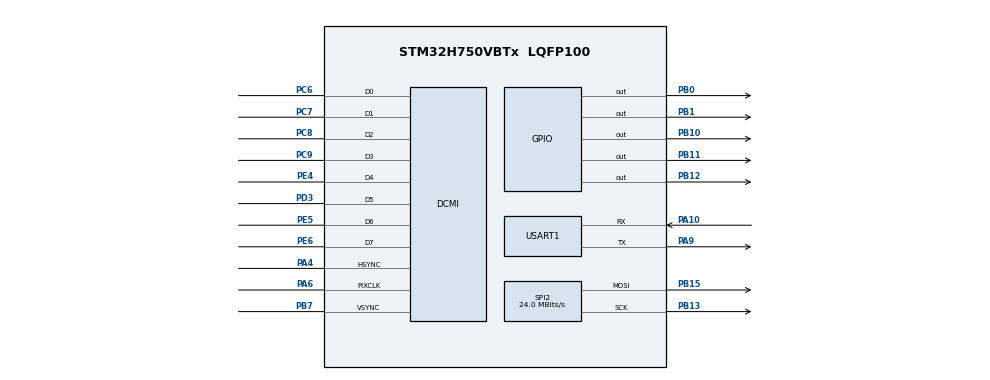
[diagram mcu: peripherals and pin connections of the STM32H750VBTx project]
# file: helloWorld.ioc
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DCMI.JPEGMode=DCMI_JPEG_ENABLE
Mcu.Family=STM32H7
Mcu.Name=STM32H750VBTx
Mcu.Package=LQFP100
NVIC.PriorityGroup=NVIC_PRIORITYGROUP_4
PA10.Mode=Asynchronous
PA10.Signal=USART1_RX
PA4.Mode=Slave_8_bits_External_Synchro
PA4.Signal=DCMI_HSYNC
PA6.Mode=Slave_8_bits_External_Synchro
PA6.Signal=DCMI_PIXCLK
PA9.Mode=Asynchronous
PA9.Signal=USART1_TX
PB0.Signal=GPIO_Output
PB1.Signal=GPIO_Output
PB10.Signal=GPIO_Output
PB11.Signal=GPIO_Output
PB12.Signal=GPIO_Output
PB13.Mode=TX_Only_Simplex_Unidirect_Master
PB13.Signal=SPI2_SCK
PB15.Mode=TX_Only_Simplex_Unidirect_Master
PB15.Signal=SPI2_MOSI
PB7.Mode=Slave_8_bits_External_Synchro
PB7.Signal=DCMI_VSYNC
PC6.Mode=Slave_8_bits_External_Synchro
PC6.Signal=DCMI_D0
PC7.Mode=Slave_8_bits_External_Synchro
PC7.Signal=DCMI_D1
PC8.Mode=Slave_8_bits_External_Synchro
PC8.Signal=DCMI_D2
PC9.Mode=Slave_8_bits_External_Synchro
PC9.Signal=DCMI_D3
PD3.Mode=Slave_8_bits_External_Synchro
PD3.Signal=DCMI_D5
PE4.Mode=Slave_8_bits_External_Synchro
PE4.Signal=DCMI_D4
PE5.Mode=Slave_8_bits_External_Synchro
PE5.Signal=DCMI_D6
PE6.Mode=Slave_8_bits_External_Synchro
PE6.Signal=DCMI_D7
ProjectManager.HeapSize=0x200
ProjectManager.StackSize=0x400
ProjectManager.TargetToolchain=MDK-ARM V5.32
RCC.ADCFreq_Value=129000000
RCC.APB1Freq_Value=120000000
RCC.APB2Freq_Value=120000000
RCC.APB3Freq_Value=120000000
RCC.APB4Freq_Value=120000000
RCC.CortexFreq_Value=480000000
RCC.D1PPRE=RCC_APB3_DIV2
RCC.D2PPRE1=RCC_APB1_DIV2
RCC.D2PPRE2=RCC_APB2_DIV2
RCC.D3PPRE=RCC_APB4_DIV2
RCC.DIVM1=4
RCC.DIVN1=60
RCC.DIVQ1=5
RCC.HCLKFreq_Value=240000000
RCC.HPRE=RCC_HCLK_DIV2
RCC.PLL2FRACN=0
RCC.PLL3FRACN=0
RCC.PLLFRACN=0
RCC.SYSCLKFreq_VALUE=480000000
RCC.SYSCLKSource=RCC_SYSCLKSOURCE_PLLCLK
RCC.USBFreq_Value=192000000
SPI2.BaudRatePrescaler=SPI_BAUDRATEPRESCALER_8
SPI2.CLKPhase=SPI_PHASE_1EDGE
SPI2.CLKPolarity=SPI_POLARITY_HIGH
SPI2.CalculateBaudRate=24.0 MBits/s
SPI2.DataSize=SPI_DATASIZE_8BIT
SPI2.Direction=SPI_DIRECTION_2LINES_TXONLY
SPI2.MasterKeepIOState=SPI_MASTER_KEEP_IO_STATE_ENABLE
SPI2.Mode=SPI_MODE_MASTER
SPI2.NSSPMode=SPI_NSS_PULSE_DISABLE
SPI2.VirtualType=VM_MASTER
USART1.VirtualMode-Asynchronous=VM_ASYNC
board=custom

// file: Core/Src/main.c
/* USER CODE BEGIN Header */
/**
  ******************************************************************************
  * @file           : main.c
  * @brief          : Main program body
  ******************************************************************************
  * @attention
  *
  * Copyright (c) 2023 STMicroelectronics.
  * All rights reserved.
  *
  * This software is licensed under terms that can be found in the LICENSE file
  * in the root directory of this software component.
  * If no LICENSE file comes with this software, it is provided AS-IS.
  *
  ******************************************************************************
  */
/* USER CODE END Header */
#include "main.h"
#include "dcmi.h"
#include "dma.h"
#include "spi.h"
#include "usart.h"
#include "gpio.h"

/* USER CODE BEGIN Includes */
#include "LCD.h"
#include "Text.h"
/* USER CODE END Includes */

void SystemClock_Config(void);

int main(void)
{

  /* MCU Configuration--------------------------------------------------------*/

  /* Reset of all peripherals, Initializes the Flash interface and the Systick. */
  HAL_Init();

  /* Configure the system clock */
  SystemClock_Config();

  /* Initialize all configured peripherals */
  MX_GPIO_Init();
  MX_DMA_Init();
  MX_SPI2_Init();
  MX_DCMI_Init();
  MX_USART1_UART_Init();
  /* USER CODE BEGIN 2 */
	LCD_Init();
	LCD_Clear(WHITE);           //清屏
	LCD_ShowString(100,100,200,5,16,BLACK,(u8 *)"RacingDooM");
  /* USER CODE END 2 */

  /* Infinite loop */
  /* USER CODE BEGIN WHILE */
  while (1)
  {
//		printf("hello world = %d",23);
//		HAL_Delay(1000);
    /* USER CODE END WHILE */

  }
}

void SystemClock_Config(void)
{
  RCC_OscInitTypeDef RCC_OscInitStruct = {0};
  RCC_ClkInitTypeDef RCC_ClkInitStruct = {0};

  /** Supply configuration update enable
  */
  HAL_PWREx_ConfigSupply(PWR_LDO_SUPPLY);

  /** Configure the main internal regulator output voltage
  */
  __HAL_PWR_VOLTAGESCALING_CONFIG(PWR_REGULATOR_VOLTAGE_SCALE1);

  while(!__HAL_PWR_GET_FLAG(PWR_FLAG_VOSRDY)) {}

  __HAL_RCC_SYSCFG_CLK_ENABLE();
  __HAL_PWR_VOLTAGESCALING_CONFIG(PWR_REGULATOR_VOLTAGE_SCALE0);

  while(!__HAL_PWR_GET_FLAG(PWR_FLAG_VOSRDY)) {}

  /** Initializes the RCC Oscillators according to the specified parameters
  * in the RCC_OscInitTypeDef structure.
  */
  RCC_OscInitStruct.OscillatorType = RCC_OSCILLATORTYPE_HSI;
  RCC_OscInitStruct.HSIState = RCC_HSI_DIV1;
  RCC_OscInitStruct.HSICalibrationValue = RCC_HSICALIBRATION_DEFAULT;
  RCC_OscInitStruct.PLL.PLLState = RCC_PLL_ON;
  RCC_OscInitStruct.PLL.PLLSource = RCC_PLLSOURCE_HSI;
  RCC_OscInitStruct.PLL.PLLM = 4;
  RCC_OscInitStruct.PLL.PLLN = 60;
  RCC_OscInitStruct.PLL.PLLP = 2;
  RCC_OscInitStruct.PLL.PLLQ = 5;
  RCC_OscInitStruct.PLL.PLLR = 2;
  RCC_OscInitStruct.PLL.PLLRGE = RCC_PLL1VCIRANGE_3;
  RCC_OscInitStruct.PLL.PLLVCOSEL = RCC_PLL1VCOWIDE;
  RCC_OscInitStruct.PLL.PLLFRACN = 0;
  if (HAL_RCC_OscConfig(&RCC_OscInitStruct) != HAL_OK)
  {
    Error_Handler();
  }

  /** Initializes the CPU, AHB and APB buses clocks
  */
  RCC_ClkInitStruct.ClockType = RCC_CLOCKTYPE_HCLK|RCC_CLOCKTYPE_SYSCLK
                              |RCC_CLOCKTYPE_PCLK1|RCC_CLOCKTYPE_PCLK2
                              |RCC_CLOCKTYPE_D3PCLK1|RCC_CLOCKTYPE_D1PCLK1;
  RCC_ClkInitStruct.SYSCLKSource = RCC_SYSCLKSOURCE_PLLCLK;
  RCC_ClkInitStruct.SYSCLKDivider = RCC_SYSCLK_DIV1;
  RCC_ClkInitStruct.AHBCLKDivider = RCC_HCLK_DIV2;
  RCC_ClkInitStruct.APB3CLKDivider = RCC_APB3_DIV2;
  RCC_ClkInitStruct.APB1CLKDivider = RCC_APB1_DIV2;
  RCC_ClkInitStruct.APB2CLKDivider = RCC_APB2_DIV2;
  RCC_ClkInitStruct.APB4CLKDivider = RCC_APB4_DIV2;

  if (HAL_RCC_ClockConfig(&RCC_ClkInitStruct, FLASH_LATENCY_4) != HAL_OK)
  {
    Error_Handler();
  }
}

void Error_Handler(void)
{
  __disable_irq();
  while (1)
  {
  }
}
